# ATmega32U4 register map
File version: 1.0
Registers are 8-bit, read-write, reset 0x0 unless marked. A register's access mark holds for its fields unless they carry their own. Offsets are from the block's base; lines under a group give offsets from that group; [hi:lo] are bit positions; {n}, {i} and the like mark numbered series; 'fields as' and 'values as' point back to an identical list; <NAME> marks a mode.

## Memory map
0x00800000 WDT — Watchdog Timer
0x00800000 PORTB — I/O Port
0x00800000 PORTC — I/O Port
0x00800000 PORTD — I/O Port
0x00800000 PORTE — I/O Port
0x00800000 PORTF — I/O Port
0x00800000 SPI — Serial Peripheral Interface
0x00800000 USART1 — USART
0x00800000 EEPROM
0x00800000 TC0 — Timer/Counter, 8-bit
0x00800000 TC0_2 — Timer/Counter, 8-bit
0x00800000 TC1 — Timer/Counter, 16-bit
0x00800000 TC3 — Timer/Counter, 16-bit
0x00800000 TC4 — Timer/Counter, 10-bit
0x00800000 TC4_2 — Timer/Counter, 10-bit
0x00800000 EXINT — External Interrupts
0x00800000 EXINT_2 — External Interrupts
0x00800000 TWI — Two Wire Serial Interface
0x00800000 ADC — Analog-to-Digital Converter
0x00800000 AC — Analog Comparator
0x00800000 PLL — Phase Locked Loop
0x00800000 PLL_2 — Phase Locked Loop

## WDT — Watchdog Timer
Base 0x00800000
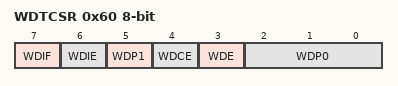
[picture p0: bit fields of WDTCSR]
0x60 WDTCSR — Watchdog Timer Control Register
  [7] WDIF — Watchdog Timeout Interrupt Flag
  [6] WDIE — Watchdog Timeout Interrupt Enable
  [5] WDP1 — Watchdog Timer Prescaler Bits
  [4] WDCE — Watchdog Change Enable
  [3] WDE — Watch Dog Enable
  [2:0] WDP0 — Watchdog Timer Prescaler Bits

## PORTB — I/O Port
Base 0x00800000
0x23 PINB — Port B Input Pins
0x24 DDRB — Port B Data Direction Register
0x25 PORTB — Port B Data Register

## PORTC — I/O Port
Base 0x00800000
0x26 PINC — Port C Input Pins
0x27 DDRC — Port C Data Direction Register
0x28 PORTC — Port C Data Register

## PORTD — I/O Port
Base 0x00800000
0x29 PIND — Port D Input Pins
0x2A DDRD — Port D Data Direction Register
0x2B PORTD — Port D Data Register

## PORTE — I/O Port
Base 0x00800000
0x2C PINE — Input Pins, Port E
0x2D DDRE — Data Direction Register, Port E
0x2E PORTE — Data Register, Port E

## PORTF — I/O Port
Base 0x00800000
0x2F PINF — Input Pins, Port F
0x30 DDRF — Data Direction Register, Port F
0x31 PORTF — Data Register, Port F

## SPI — Serial Peripheral Interface
Base 0x00800000
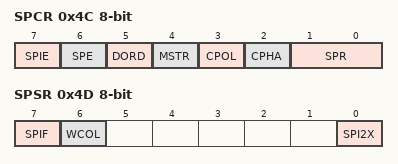
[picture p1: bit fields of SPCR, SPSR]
0x4C SPCR — SPI Control Register
  [7] SPIE — SPI Interrupt Enable
  [6] SPE — SPI Enable
  [5] DORD — Data Order
  [4] MSTR — Master/Slave Select
  [3] CPOL — Clock polarity
  [2] CPHA — Clock Phase
  [1:0] SPR — SPI Clock Rate Selects
0x4D SPSR — SPI Status Register
  [7] SPIF — SPI Interrupt Flag
  [6] WCOL — Write Collision Flag
  [0] SPI2X — Double SPI Speed Bit

## USART1 — USART
Base 0x00800000
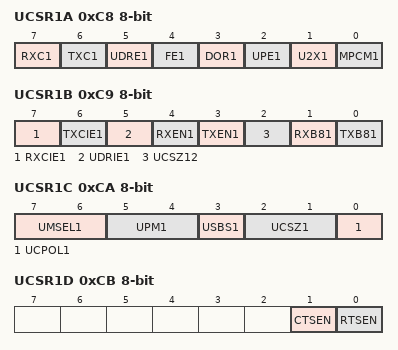
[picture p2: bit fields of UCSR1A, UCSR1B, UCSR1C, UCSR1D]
0xC8 UCSR1A — USART Control and Status Register A
  [7] RXC1 — USART Receive Complete
  [6] TXC1 — USART Transmitt Complete
  [5] UDRE1 — USART Data Register Empty
  [4] FE1 — Framing Error
  [3] DOR1 — Data overRun
  [2] UPE1 — Parity Error
  [1] U2X1 — Double the USART transmission speed
  [0] MPCM1 — Multi-processor Communication Mode
0xC9 UCSR1B — USART Control and Status Register B
  [7] RXCIE1 — RX Complete Interrupt Enable
  [6] TXCIE1 — TX Complete Interrupt Enable
  [5] UDRIE1 — USART Data register Empty Interrupt Enable
  [4] RXEN1 — Receiver Enable
  [3] TXEN1 — Transmitter Enable
  [2] UCSZ12 — Character Size
  [1] RXB81 — Receive Data Bit 8
  [0] TXB81 — Transmit Data Bit 8
0xCA UCSR1C — USART Control and Status Register C
  [7:6] UMSEL1 — USART Mode Select
  [5:4] UPM1 — Parity Mode Bits
  [3] USBS1 — Stop Bit Select
  [2:1] UCSZ1 — Character Size
  [0] UCPOL1 — Clock Polarity
0xCB UCSR1D — USART Control and Status Register D
  [1] CTSEN — CTS Enable
  [0] RTSEN — RTS Enable
0xCC UBRR1 16-bit (reset mask 0xFF) — USART Baud Rate Register Bytes

## EEPROM
Base 0x00800000
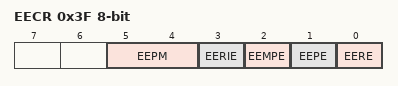
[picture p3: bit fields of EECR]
0x3F EECR — EEPROM Control Register
  [5:4] EEPM — EEPROM Programming Mode Bits
  [3] EERIE — EEPROM Ready Interrupt Enable
  [2] EEMPE — EEPROM Master Write Enable
  [1] EEPE — EEPROM Write Enable
  [0] EERE — EEPROM Read Enable
0x40 EEDR — EEPROM Data Register
0x41 EEAR 16-bit (reset mask 0xFF) — EEPROM Address Register Low Bytes
